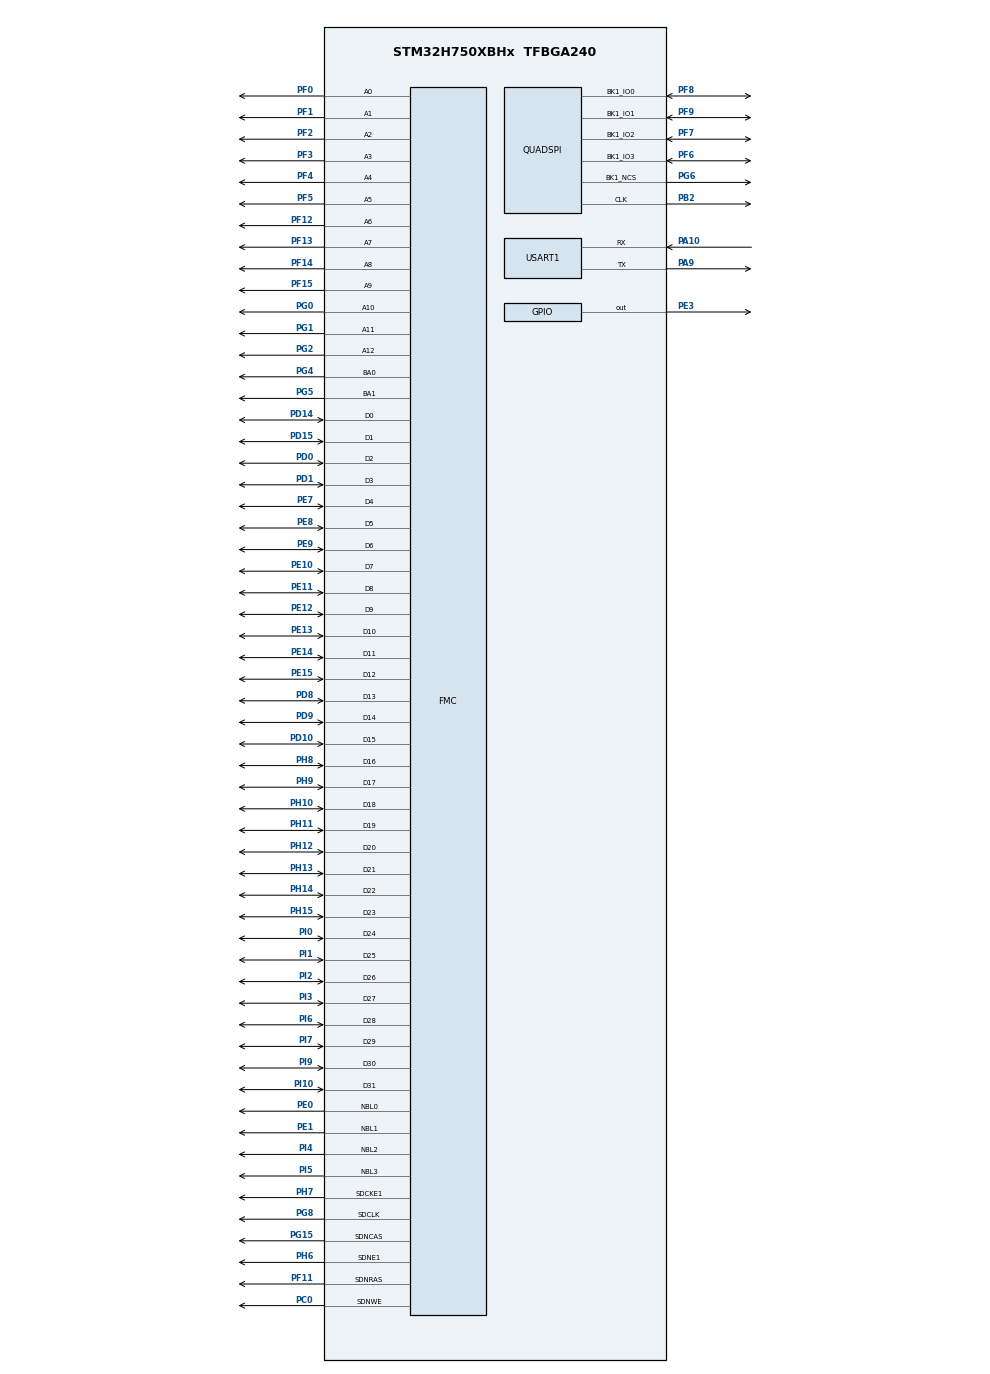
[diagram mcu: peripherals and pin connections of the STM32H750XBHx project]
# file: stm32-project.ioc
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CORTEX_M7.CPU_DCache=Enabled
CORTEX_M7.CPU_ICache=Enabled
FMC.CASLatency1=FMC_SDRAM_CAS_LATENCY_3
FMC.ColumnBitsNumber1=FMC_SDRAM_COLUMN_BITS_NUM_9
FMC.ExitSelfRefreshDelay1=8
FMC.LoadToActiveDelay1=2
FMC.RCDDelay1=2
FMC.RPDelay1=2
FMC.ReadBurst1=FMC_SDRAM_RBURST_ENABLE
FMC.ReadPipeDelay1=FMC_SDRAM_RPIPE_DELAY_1
FMC.RowCycleDelay1=8
FMC.SDClockPeriod1=FMC_SDRAM_CLOCK_PERIOD_2
FMC.SelfRefreshTime1=5
FMC.WriteRecoveryTime1=4
Mcu.Family=STM32H7
Mcu.Name=STM32H750XBHx
Mcu.Package=TFBGA240
NVIC.PriorityGroup=NVIC_PRIORITYGROUP_4
NVIC.TIM6_DAC_IRQn=true\:15\:0\:false\:false\:true\:false\:true\:true
NVIC.TIM7_IRQn=true\:0\:0\:false\:false\:true\:true\:true\:true
NVIC.TimeBase=TIM6_DAC_IRQn
NVIC.TimeBaseIP=TIM6
PA10.Mode=Asynchronous
PA10.Signal=USART1_RX
PA13\ (JTMS/SWDIO).Mode=Serial_Wire
PA13\ (JTMS/SWDIO).Signal=DEBUG_JTMS-SWDIO
PA14\ (JTCK/SWCLK).Mode=Serial_Wire
PA14\ (JTCK/SWCLK).Signal=DEBUG_JTCK-SWCLK
PA9.Mode=Asynchronous
PA9.Signal=USART1_TX
PB2.GPIO_Speed=GPIO_SPEED_FREQ_VERY_HIGH
PB2.Mode=Single Bank 1
PB2.Signal=QUADSPI_CLK
PC0.Signal=FMC_SDNWE
PD0.Signal=FMC_D2_DA2
PD1.Signal=FMC_D3_DA3
PD10.Signal=FMC_D15_DA15
PD14.Signal=FMC_D0_DA0
PD15.Signal=FMC_D1_DA1
PD8.Signal=FMC_D13_DA13
PD9.Signal=FMC_D14_DA14
PE0.Signal=FMC_NBL0
PE1.Signal=FMC_NBL1
PE10.Signal=FMC_D7_DA7
PE11.Signal=FMC_D8_DA8
PE12.Signal=FMC_D9_DA9
PE13.Signal=FMC_D10_DA10
PE14.Signal=FMC_D11_DA11
PE15.Signal=FMC_D12_DA12
PE3.Signal=GPIO_Output
PE7.Signal=FMC_D4_DA4
PE8.Signal=FMC_D5_DA5
PE9.Signal=FMC_D6_DA6
PF0.Signal=FMC_A0
PF1.Signal=FMC_A1
PF11.Signal=FMC_SDNRAS
PF12.Signal=FMC_A6
PF13.Signal=FMC_A7
PF14.Signal=FMC_A8
PF15.Signal=FMC_A9
PF2.Signal=FMC_A2
PF3.Signal=FMC_A3
PF4.Signal=FMC_A4
PF5.Signal=FMC_A5
PF6.GPIO_Speed=GPIO_SPEED_FREQ_VERY_HIGH
PF6.Mode=Single Bank 1
PF6.Signal=QUADSPI_BK1_IO3
PF7.GPIO_Speed=GPIO_SPEED_FREQ_VERY_HIGH
PF7.Mode=Single Bank 1
PF7.Signal=QUADSPI_BK1_IO2
PF8.GPIO_Speed=GPIO_SPEED_FREQ_VERY_HIGH
PF8.Mode=Single Bank 1
PF8.Signal=QUADSPI_BK1_IO0
PF9.GPIO_Speed=GPIO_SPEED_FREQ_VERY_HIGH
PF9.Mode=Single Bank 1
PF9.Signal=QUADSPI_BK1_IO1
PG0.Signal=FMC_A10
PG1.Signal=FMC_A11
PG15.Signal=FMC_SDNCAS
PG2.Signal=FMC_A12
PG4.Signal=FMC_A14_BA0
PG5.Signal=FMC_A15_BA1
PG6.GPIO_Speed=GPIO_SPEED_FREQ_VERY_HIGH
PG6.Mode=Single Bank 1
PG6.Signal=QUADSPI_BK1_NCS
PG8.Signal=FMC_SDCLK
PH0-OSC_IN\ (PH0).Mode=HSE-External-Oscillator
PH0-OSC_IN\ (PH0).Signal=RCC_OSC_IN
PH1-OSC_OUT\ (PH1).Mode=HSE-External-Oscillator
PH1-OSC_OUT\ (PH1).Signal=RCC_OSC_OUT
PH10.Signal=FMC_D18
PH11.Signal=FMC_D19
PH12.Signal=FMC_D20
PH13.Signal=FMC_D21
PH14.Signal=FMC_D22
PH15.Signal=FMC_D23
PH6.Mode=SdramChipSelect2_1
PH6.Signal=FMC_SDNE1
PH7.Mode=SdramChipSelect2_1
PH7.Signal=FMC_SDCKE1
PH8.Signal=FMC_D16
PH9.Signal=FMC_D17
PI0.Signal=FMC_D24
PI1.Signal=FMC_D25
PI10.Signal=FMC_D31
PI2.Signal=FMC_D26
PI3.Signal=FMC_D27
PI4.Signal=FMC_NBL2
PI5.Signal=FMC_NBL3
PI6.Signal=FMC_D28
PI7.Signal=FMC_D29
PI9.Signal=FMC_D30
ProjectManager.HeapSize=0x2000
ProjectManager.StackSize=0x1000
ProjectManager.TargetToolchain=MDK-ARM V5.32
QUADSPI.ChipSelectHighTime=QSPI_CS_HIGH_TIME_6_CYCLE
QUADSPI.ClockMode=QSPI_CLOCK_MODE_3
QUADSPI.ClockPrescaler=1
QUADSPI.FifoThreshold=24
QUADSPI.FlashSize=24
QUADSPI.SampleShifting=QSPI_SAMPLE_SHIFTING_HALFCYCLE
RCC.ADCFreq_Value=360000000
RCC.APB1CLKDivider=RCC_HCLK_DIV4
RCC.APB1Freq_Value=120000000
RCC.APB2CLKDivider=RCC_HCLK_DIV2
RCC.APB2Freq_Value=120000000
RCC.APB3Freq_Value=120000000
RCC.APB4Freq_Value=120000000
RCC.CortexFreq_Value=480000000
RCC.D1PPRE=RCC_APB3_DIV2
RCC.D2PPRE1=RCC_APB1_DIV2
RCC.D2PPRE2=RCC_APB2_DIV2
RCC.D3PPRE=RCC_APB4_DIV2
RCC.DIVM1=5
RCC.DIVM2=5
RCC.DIVM3=5
RCC.DIVN1=192
RCC.DIVN2=144
RCC.DIVN3=480
RCC.DIVQ1=20
RCC.DIVQ3=8
RCC.DIVR2=3
RCC.FLatency=FLASH_LATENCY_4
RCC.FMCCLockSelection=RCC_FMCCLKSOURCE_PLL2
RCC.HCLKFreq_Value=240000000
RCC.HPRE=RCC_HCLK_DIV2
RCC.HSE_VALUE=25000000
RCC.PLLFRACN=0
RCC.PLLM=25
RCC.PLLMUL=RCC_PLL_MUL9
RCC.PLLN=432
RCC.PLLQ=9
RCC.PLLSourceVirtual=RCC_PLLSOURCE_HSE
RCC.PRESCALERUSB=RCC_USBCLKSOURCE_PLL_DIV1_5
RCC.PWR_Regulator_Voltage_Scale=PWR_REGULATOR_VOLTAGE_SCALE0
RCC.ProductRev=revV
RCC.SYSCLKFreq_VALUE=480000000
RCC.SYSCLKSource=RCC_SYSCLKSOURCE_PLLCLK
RCC.SYSCLKSourceVirtual=RCC_SYSCLKSOURCE_PLLCLK
RCC.USBFreq_Value=48000000
SH.FMC_A0.0=FMC_A0,13b-sda1
SH.FMC_A1.0=FMC_A1,13b-sda1
SH.FMC_A10.0=FMC_A10,13b-sda1
SH.FMC_A11.0=FMC_A11,13b-sda1
SH.FMC_A12.0=FMC_A12,13b-sda1
SH.FMC_A14_BA0.0=FMC_BA0,FourSdramBanks1
SH.FMC_A15_BA1.0=FMC_BA1,FourSdramBanks1
SH.FMC_A2.0=FMC_A2,13b-sda1
SH.FMC_A3.0=FMC_A3,13b-sda1
SH.FMC_A4.0=FMC_A4,13b-sda1
SH.FMC_A5.0=FMC_A5,13b-sda1
SH.FMC_A6.0=FMC_A6,13b-sda1
SH.FMC_A7.0=FMC_A7,13b-sda1
SH.FMC_A8.0=FMC_A8,13b-sda1
SH.FMC_A9.0=FMC_A9,13b-sda1
SH.FMC_D0_DA0.0=FMC_D0,sd-32b-d1
SH.FMC_D10_DA10.0=FMC_D10,sd-32b-d1
SH.FMC_D11_DA11.0=FMC_D11,sd-32b-d1
SH.FMC_D12_DA12.0=FMC_D12,sd-32b-d1
SH.FMC_D13_DA13.0=FMC_D13,sd-32b-d1
SH.FMC_D14_DA14.0=FMC_D14,sd-32b-d1
SH.FMC_D15_DA15.0=FMC_D15,sd-32b-d1
SH.FMC_D16.0=FMC_D16,sd-32b-d1
SH.FMC_D17.0=FMC_D17,sd-32b-d1
SH.FMC_D18.0=FMC_D18,sd-32b-d1
SH.FMC_D19.0=FMC_D19,sd-32b-d1
SH.FMC_D1_DA1.0=FMC_D1,sd-32b-d1
SH.FMC_D20.0=FMC_D20,sd-32b-d1
SH.FMC_D21.0=FMC_D21,sd-32b-d1
SH.FMC_D22.0=FMC_D22,sd-32b-d1
SH.FMC_D23.0=FMC_D23,sd-32b-d1
SH.FMC_D24.0=FMC_D24,sd-32b-d1
SH.FMC_D25.0=FMC_D25,sd-32b-d1
SH.FMC_D26.0=FMC_D26,sd-32b-d1
SH.FMC_D27.0=FMC_D27,sd-32b-d1
SH.FMC_D28.0=FMC_D28,sd-32b-d1
SH.FMC_D29.0=FMC_D29,sd-32b-d1
SH.FMC_D2_DA2.0=FMC_D2,sd-32b-d1
SH.FMC_D30.0=FMC_D30,sd-32b-d1
SH.FMC_D31.0=FMC_D31,sd-32b-d1
SH.FMC_D3_DA3.0=FMC_D3,sd-32b-d1
SH.FMC_D4_DA4.0=FMC_D4,sd-32b-d1
SH.FMC_D5_DA5.0=FMC_D5,sd-32b-d1
SH.FMC_D6_DA6.0=FMC_D6,sd-32b-d1
SH.FMC_D7_DA7.0=FMC_D7,sd-32b-d1
SH.FMC_D8_DA8.0=FMC_D8,sd-32b-d1
SH.FMC_D9_DA9.0=FMC_D9,sd-32b-d1
SH.FMC_NBL0.0=FMC_NBL0,Sd4ByteEnable1
SH.FMC_NBL1.0=FMC_NBL1,Sd4ByteEnable1
SH.FMC_NBL2.0=FMC_NBL2,Sd4ByteEnable1
SH.FMC_NBL3.0=FMC_NBL3,Sd4ByteEnable1
SH.FMC_SDCLK.0=FMC_SDCLK,13b-sda1
SH.FMC_SDNCAS.0=FMC_SDNCAS,13b-sda1
SH.FMC_SDNRAS.0=FMC_SDNRAS,13b-sda1
SH.FMC_SDNWE.0=FMC_SDNWE,13b-sda1
STMicroelectronics.X-CUBE-AI.8.1.0.ActivationBufferSizeList=4940
STMicroelectronics.X-CUBE-AI.8.1.0.ActivationBuffers=pool0
STMicroelectronics.X-CUBE-AI.8.1.0.ActivationNames=pool0
STMicroelectronics.X-CUBE-AI.8.1.0.ActivationSizes=AI_MNIST_DATA_ACTIVATION_1_SIZE
STMicroelectronics.X-CUBE-AI.8.1.0.ApplicationCcDeviceJjApplication=ApplicationTemplate
STMicroelectronics.X-CUBE-AI.8.1.0.HeapSize=0x2000
STMicroelectronics.X-CUBE-AI.8.1.0.InternalRamActivationBufferMaxSize=AI_MNIST_DATA_ACTIVATIONS_SIZE
STMicroelectronics.X-CUBE-AI.8.1.0.LatestDirectoryUsed-1ee2e7aae18cbfe4b4495ff60675ee051ff56629e01ddfafbf7e7a2405e25b5f=D\:\\A\\Github-repo\\Dareka\\Software\\minist\\model
STMicroelectronics.X-CUBE-AI.8.1.0.MaximumNumberOfInputLayer=1
STMicroelectronics.X-CUBE-AI.8.1.0.MaximumNumberOfOutputLayer=1
STMicroelectronics.X-CUBE-AI.8.1.0.MaximumSizeOfInputLayer=1
STMicroelectronics.X-CUBE-AI.8.1.0.MaximumSizeOfOutputLayer=1
STMicroelectronics.X-CUBE-AI.8.1.0.ModelActualCompression-1ee2e7aae18cbfe4b4495ff60675ee051ff56629e01ddfafbf7e7a2405e25b5f=3.838437
STMicroelectronics.X-CUBE-AI.8.1.0.ModelCompression-1ee2e7aae18cbfe4b4495ff60675ee051ff56629e01ddfafbf7e7a2405e25b5f=Low
STMicroelectronics.X-CUBE-AI.8.1.0.ModelFlashOccupation-1ee2e7aae18cbfe4b4495ff60675ee051ff56629e01ddfafbf7e7a2405e25b5f=67874
STMicroelectronics.X-CUBE-AI.8.1.0.ModelHashList=1ee2e7aae18cbfe4b4495ff60675ee051ff56629e01ddfafbf7e7a2405e25b5f
STMicroelectronics.X-CUBE-AI.8.1.0.ModelKind-1ee2e7aae18cbfe4b4495ff60675ee051ff56629e01ddfafbf7e7a2405e25b5f=TFLITE
STMicroelectronics.X-CUBE-AI.8.1.0.ModelMacc-1ee2e7aae18cbfe4b4495ff60675ee051ff56629e01ddfafbf7e7a2405e25b5f=51104
STMicroelectronics.X-CUBE-AI.8.1.0.ModelName-1ee2e7aae18cbfe4b4495ff60675ee051ff56629e01ddfafbf7e7a2405e25b5f=mnist
STMicroelectronics.X-CUBE-AI.8.1.0.ModelNameList=mnist
STMicroelectronics.X-CUBE-AI.8.1.0.ModelRamOccupation-1ee2e7aae18cbfe4b4495ff60675ee051ff56629e01ddfafbf7e7a2405e25b5f=4940
STMicroelectronics.X-CUBE-AI.8.1.0.ModelStructureFile-1ee2e7aae18cbfe4b4495ff60675ee051ff56629e01ddfafbf7e7a2405e25b5f=D\:\\A\\Github-repo\\Dareka\\Software\\minist\\model\\mnist_quantized_model.tflite
STMicroelectronics.X-CUBE-AI.8.1.0.ModelType-1ee2e7aae18cbfe4b4495ff60675ee051ff56629e01ddfafbf7e7a2405e25b5f=STM32Cube.AI runtime
STMicroelectronics.X-CUBE-AI.8.1.0.ReadyForCodeGeneration=true
STMicroelectronics.X-CUBE-AI.8.1.0.StackSize=0x1000
STMicroelectronics.X-CUBE-AI.8.1.0.WorkingBufferStartAddrList=0xFFFFFFFF
STMicroelectronics.X-CUBE-AI.8.1.0.XAaCUBEAaAICcArtificialOoIntelligenceJjCore=true
STMicroelectronics.X-CUBE-AI.8.1.0.copyWeightToRam=false
STMicroelectronics.X-CUBE-AI.8.1.0.copyWeightToRam-1ee2e7aae18cbfe4b4495ff60675ee051ff56629e01ddfafbf7e7a2405e25b5f=false
STMicroelectronics.X-CUBE-AI.8.1.0.customLayerConfigEnabled=false
STMicroelectronics.X-CUBE-AI.8.1.0.customLayerConfigEnabled-1ee2e7aae18cbfe4b4495ff60675ee051ff56629e01ddfafbf7e7a2405e25b5f=false
STMicroelectronics.X-CUBE-AI.8.1.0.noOnnxIoTranspose=false
STMicroelectronics.X-CUBE-AI.8.1.0.noOnnxIoTranspose-1ee2e7aae18cbfe4b4495ff60675ee051ff56629e01ddfafbf7e7a2405e25b5f=false
STMicroelectronics.X-CUBE-AI.8.1.0.useInputAllocation=true
STMicroelectronics.X-CUBE-AI.8.1.0.useInputAllocation-1ee2e7aae18cbfe4b4495ff60675ee051ff56629e01ddfafbf7e7a2405e25b5f=true
STMicroelectronics.X-CUBE-AI.8.1.0.useOutputAllocation=true
STMicroelectronics.X-CUBE-AI.8.1.0.useOutputAllocation-1ee2e7aae18cbfe4b4495ff60675ee051ff56629e01ddfafbf7e7a2405e25b5f=true
TIM7.AutoReloadPreload=TIM_AUTORELOAD_PRELOAD_ENABLE
TIM7.Period=10000
TIM7.Prescaler=24
USART1.VirtualMode-Asynchronous=VM_ASYNC
VP_CRC_VS_CRC.Mode=CRC_Activate
VP_STMicroelectronics.X-CUBE-AI_VS_ArtificialOoIntelligenceJjXAaCUBEAaAI_8.1.0.Mode=ArtificialOoIntelligenceJjXAaCUBEAaAI
VP_STMicroelectronics.X-CUBE-AI_VS_DeviceJjApplication_8.1.0.Mode=DeviceJjApplication
VP_SYS_VS_tim6.Mode=TIM6
VP_TIM7_VS_ClockSourceINT.Mode=Enable_Timer
board=custom

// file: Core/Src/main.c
/* USER CODE BEGIN Header */
/**
  ******************************************************************************
  * @file           : main.c
  * @brief          : Main program body
  ******************************************************************************
  * @attention
  *
  * Copyright (c) 2023 STMicroelectronics.
  * All rights reserved.
  *
  * This software is licensed under terms that can be found in the LICENSE file
  * in the root directory of this software component.
  * If no LICENSE file comes with this software, it is provided AS-IS.
  *
  ******************************************************************************
  */
/* USER CODE END Header */
#include "main.h"
#include "crc.h"
#include "quadspi.h"
#include "tim.h"
#include "usart.h"
#include "gpio.h"
#include "fmc.h"
#include "app_x-cube-ai.h"

/* USER CODE BEGIN Includes */
#include "user_main.h"
/* USER CODE END Includes */

void SystemClock_Config(void);

int main(void)
{

  /* Enable the CPU Cache */

  /* Enable I-Cache---------------------------------------------------------*/
  SCB_EnableICache();

  /* Enable D-Cache---------------------------------------------------------*/
  SCB_EnableDCache();

  /* MCU Configuration--------------------------------------------------------*/

  /* Reset of all peripherals, Initializes the Flash interface and the Systick. */
  HAL_Init();

  /* Configure the system clock */
  SystemClock_Config();

  /* USER CODE BEGIN SysInit */
	__HAL_RCC_D2SRAM1_CLK_ENABLE();
  /* USER CODE END SysInit */

  /* Initialize all configured peripherals */
  MX_GPIO_Init();
  MX_TIM7_Init();
  MX_USART1_UART_Init();
  MX_FMC_Init();
  MX_QUADSPI_Init();
  MX_CRC_Init();
  /* USER CODE BEGIN 2 */
    user_main();
  /* USER CODE END 2 */

  /* Infinite loop */
  /* USER CODE BEGIN WHILE */
  while (1)
  {
	  HAL_Delay(500);
    /* USER CODE END WHILE */

  MX_X_CUBE_AI_Process();
  }
}

void SystemClock_Config(void)
{
  RCC_OscInitTypeDef RCC_OscInitStruct = {0};
  RCC_ClkInitTypeDef RCC_ClkInitStruct = {0};

  /** Supply configuration update enable
  */
  HAL_PWREx_ConfigSupply(PWR_LDO_SUPPLY);

  /** Configure the main internal regulator output voltage
  */
  __HAL_PWR_VOLTAGESCALING_CONFIG(PWR_REGULATOR_VOLTAGE_SCALE1);

  while(!__HAL_PWR_GET_FLAG(PWR_FLAG_VOSRDY)) {}

  __HAL_RCC_SYSCFG_CLK_ENABLE();
  __HAL_PWR_VOLTAGESCALING_CONFIG(PWR_REGULATOR_VOLTAGE_SCALE0);

  while(!__HAL_PWR_GET_FLAG(PWR_FLAG_VOSRDY)) {}

  /** Initializes the RCC Oscillators according to the specified parameters
  * in the RCC_OscInitTypeDef structure.
  */
  RCC_OscInitStruct.OscillatorType = RCC_OSCILLATORTYPE_HSE;
  RCC_OscInitStruct.HSEState = RCC_HSE_ON;
  RCC_OscInitStruct.PLL.PLLState = RCC_PLL_ON;
  RCC_OscInitStruct.PLL.PLLSource = RCC_PLLSOURCE_HSE;
  RCC_OscInitStruct.PLL.PLLM = 5;
  RCC_OscInitStruct.PLL.PLLN = 192;
  RCC_OscInitStruct.PLL.PLLP = 2;
  RCC_OscInitStruct.PLL.PLLQ = 20;
  RCC_OscInitStruct.PLL.PLLR = 2;
  RCC_OscInitStruct.PLL.PLLRGE = RCC_PLL1VCIRANGE_2;
  RCC_OscInitStruct.PLL.PLLVCOSEL = RCC_PLL1VCOWIDE;
  RCC_OscInitStruct.PLL.PLLFRACN = 0;
  if (HAL_RCC_OscConfig(&RCC_OscInitStruct) != HAL_OK)
  {
    Error_Handler();
  }

  /** Initializes the CPU, AHB and APB buses clocks
  */
  RCC_ClkInitStruct.ClockType = RCC_CLOCKTYPE_HCLK|RCC_CLOCKTYPE_SYSCLK
                              |RCC_CLOCKTYPE_PCLK1|RCC_CLOCKTYPE_PCLK2
                              |RCC_CLOCKTYPE_D3PCLK1|RCC_CLOCKTYPE_D1PCLK1;
  RCC_ClkInitStruct.SYSCLKSource = RCC_SYSCLKSOURCE_PLLCLK;
  RCC_ClkInitStruct.SYSCLKDivider = RCC_SYSCLK_DIV1;
  RCC_ClkInitStruct.AHBCLKDivider = RCC_HCLK_DIV2;
  RCC_ClkInitStruct.APB3CLKDivider = RCC_APB3_DIV2;
  RCC_ClkInitStruct.APB1CLKDivider = RCC_APB1_DIV2;
  RCC_ClkInitStruct.APB2CLKDivider = RCC_APB2_DIV2;
  RCC_ClkInitStruct.APB4CLKDivider = RCC_APB4_DIV2;

  if (HAL_RCC_ClockConfig(&RCC_ClkInitStruct, FLASH_LATENCY_4) != HAL_OK)
  {
    Error_Handler();
  }
}

void HAL_TIM_PeriodElapsedCallback(TIM_HandleTypeDef *htim)
{
  if (htim->Instance == TIM6) {
    HAL_IncTick();
  }
}

void Error_Handler(void)
{
  __disable_irq();
  while (1)
  {
  }
}
